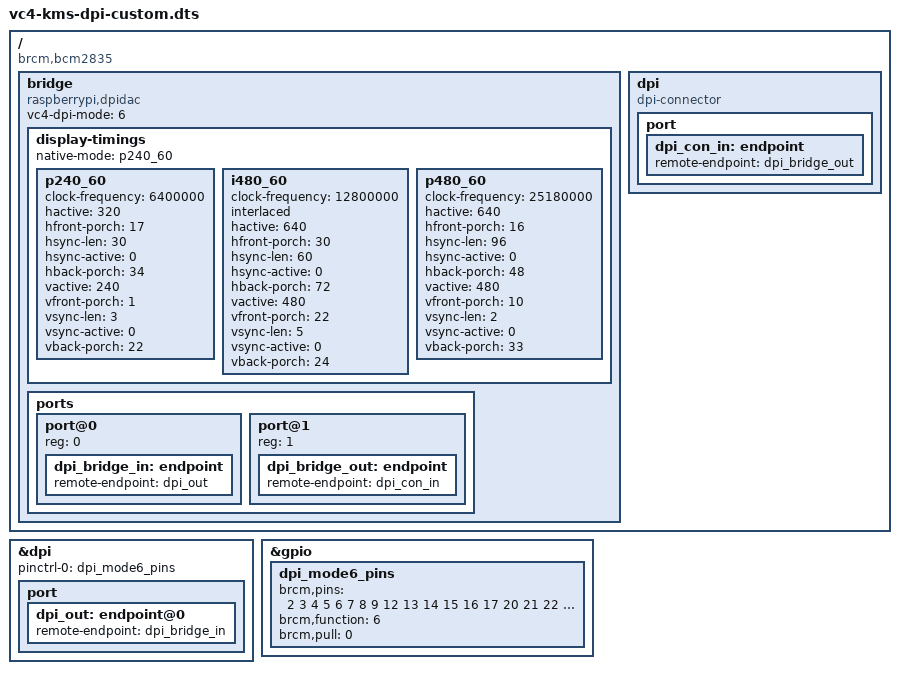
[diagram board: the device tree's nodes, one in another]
/dts-v1/;
/plugin/;

/ {
	compatible = "brcm,bcm2835", "brcm,bcm2708", "brcm,bcm2709", "brcm,bcm2712";

	fragment@0 {
		target-path = "/";
		__overlay__ {
			bridge: bridge {
				compatible = "raspberrypi,dpidac";
				#address-cells = <1>;
				#size-cells = <0>;

				vc4-dpi-mode = <6>;

				display-timings {
					native-mode = <&p240_60>;

					p240_60: p240_60 {
						clock-frequency = <6400000>;
						hactive = <320>;
						hfront-porch = <17>;
						hsync-len = <30>;
						hsync-active = <0>;
						hback-porch = <34>;
						vactive = <240>;
						vfront-porch = <1>;
						vsync-len = <3>;
						vsync-active = <0>;
						vback-porch = <22>;
					};
					
					i480_60: i480_60 {
						clock-frequency = <12800000>;
						interlaced;
						hactive = <640>;
						hfront-porch = <30>;
						hsync-len = <60>;
						hsync-active = <0>;
						hback-porch = <72>;
						vactive = <480>;
						vfront-porch = <22>;
						vsync-len = <5>;
						vsync-active = <0>;
						vback-porch = <24>;
					};
					
					p480_60: p480_60 {
						clock-frequency = <25180000>;
						hactive = <640>;
						hfront-porch = <16>;
						hsync-len = <96>;
						hsync-active = <0>;
						hback-porch = <48>;
						vactive = <480>;
						vfront-porch = <10>;
						vsync-len = <2>;
						vsync-active = <0>;
						vback-porch = <33>;
					};
				};

				ports {
					#address-cells = <1>;
					#size-cells = <0>;

					port@0 {
						reg = <0>;

						dpi_bridge_in: endpoint {
							remote-endpoint = <&dpi_out>;
						};
					};

					port@1 {
						reg = <1>;

						dpi_bridge_out: endpoint {
							remote-endpoint = <&dpi_con_in>;
						};
					};
				};
			};

			dpi {
				compatible = "dpi-connector";

				port {
					dpi_con_in: endpoint {
						remote-endpoint = <&dpi_bridge_out>;
					};
				};
			};
		};
	};

	fragment@1 {
		target = <&dpi>;
		__overlay__  {
			status = "okay";
			pinctrl-names = "default";
			pinctrl-0 = <&dpi_mode6_pins>;
			port {
				dpi_out: endpoint@0 {
					remote-endpoint = <&dpi_bridge_in>;
				};
			};
		};
	};

	fragment@2 {
		target = <&gpio>;
		__overlay__ {
			dpi_mode6_pins: dpi_mode6_pins {
				brcm,pins = <2 3 4 5 6 7 8 9 12 13 14
						 15 16 17 20 21 22 23 24 25>;
				brcm,function = <6>;
				brcm,pull = <0>;
			};
		};
	};
};
